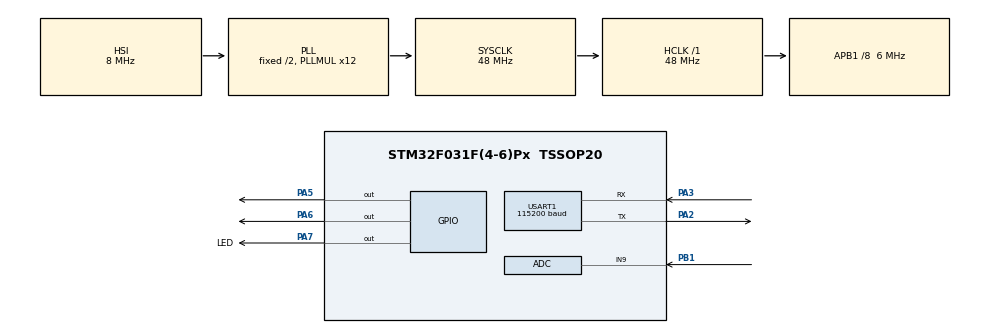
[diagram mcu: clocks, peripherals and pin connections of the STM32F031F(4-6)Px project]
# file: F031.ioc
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ADC.ClockPrescaler=ADC_CLOCK_ASYNC_DIV1
ADC.ContinuousConvMode=ENABLE
Dma.ADC.0.Direction=DMA_PERIPH_TO_MEMORY
Dma.ADC.0.Instance=DMA1_Channel1
Dma.ADC.0.MemDataAlignment=DMA_MDATAALIGN_HALFWORD
Dma.ADC.0.MemInc=DMA_MINC_ENABLE
Dma.ADC.0.Mode=DMA_NORMAL
Dma.ADC.0.PeriphDataAlignment=DMA_PDATAALIGN_HALFWORD
Dma.ADC.0.PeriphInc=DMA_PINC_DISABLE
Dma.ADC.0.Priority=DMA_PRIORITY_LOW
Dma.Request0=ADC
Dma.Request1=USART1_RX
Dma.Request2=USART1_TX
Dma.USART1_RX.1.Direction=DMA_PERIPH_TO_MEMORY
Dma.USART1_RX.1.Instance=DMA1_Channel3
Dma.USART1_RX.1.MemDataAlignment=DMA_MDATAALIGN_BYTE
Dma.USART1_RX.1.MemInc=DMA_MINC_ENABLE
Dma.USART1_RX.1.Mode=DMA_NORMAL
Dma.USART1_RX.1.PeriphDataAlignment=DMA_PDATAALIGN_BYTE
Dma.USART1_RX.1.PeriphInc=DMA_PINC_DISABLE
Dma.USART1_RX.1.Priority=DMA_PRIORITY_LOW
Dma.USART1_TX.2.Direction=DMA_MEMORY_TO_PERIPH
Dma.USART1_TX.2.Instance=DMA1_Channel2
Dma.USART1_TX.2.MemDataAlignment=DMA_MDATAALIGN_BYTE
Dma.USART1_TX.2.MemInc=DMA_MINC_ENABLE
Dma.USART1_TX.2.Mode=DMA_NORMAL
Dma.USART1_TX.2.PeriphDataAlignment=DMA_PDATAALIGN_BYTE
Dma.USART1_TX.2.PeriphInc=DMA_PINC_DISABLE
Dma.USART1_TX.2.Priority=DMA_PRIORITY_LOW
Mcu.Family=STM32F0
Mcu.Name=STM32F031F(4-6)Px
Mcu.Package=TSSOP20
NVIC.DMA1_Channel1_IRQn=true\:3\:0\:true\:false\:true\:false\:true\:true
NVIC.DMA1_Channel2_3_IRQn=true\:1\:0\:true\:false\:true\:false\:true\:true
NVIC.PVD_IRQn=true\:3\:0\:true\:false\:true\:true\:true\:true
PA13.Mode=Serial_Wire
PA13.Signal=SYS_SWDIO
PA14.Mode=Serial_Wire
PA14.Signal=SYS_SWCLK
PA2.Mode=Asynchronous
PA2.Signal=USART1_TX
PA3.Mode=Asynchronous
PA3.Signal=USART1_RX
PA5.Signal=GPIO_Output
PA6.Signal=GPIO_Output
PA7.GPIO_Label=LED
PA7.Signal=GPIO_Output
PB1.Mode=IN9
PB1.Signal=ADC_IN9
ProjectManager.HeapSize=0x200
ProjectManager.StackSize=0x400
ProjectManager.TargetToolchain=EWARM V7
RCC.AHBFreq_Value=48000000
RCC.APB1CLKDivider=RCC_HCLK_DIV8
RCC.APB1Freq_Value=6000000
RCC.APB1TimFreq_Value=12000000
RCC.HCLKFreq_Value=48000000
RCC.PLLMUL=RCC_PLL_MUL12
RCC.SYSCLKFreq_VALUE=48000000
RCC.SYSCLKSource=RCC_SYSCLKSOURCE_PLLCLK
RCC.Usart1ClockSelection=RCC_USART1CLKSOURCE_SYSCLK
USART1.BaudRate=115200
USART1.OverSampling=UART_OVERSAMPLING_8
USART1.VirtualMode-Asynchronous=VM_ASYNC
VP_ADC_TempSens_Input.Mode=IN-TempSens
VP_ADC_Vref_Input.Mode=IN-Vrefint
board=custom

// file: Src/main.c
/* USER CODE BEGIN Header */
/**
  ******************************************************************************
  * @file           : main.c
  * @brief          : Main program body
  ******************************************************************************
  * @attention
  *
  * Copyright (c) 2024 STMicroelectronics.
  * All rights reserved.
  *
  * This software is licensed under terms that can be found in the LICENSE file
  * in the root directory of this software component.
  * If no LICENSE file comes with this software, it is provided AS-IS.
  *
  ******************************************************************************
  */
/* USER CODE END Header */
#include "main.h"

ADC_HandleTypeDef hadc;
DMA_HandleTypeDef hdma_adc;

void SystemClock_Config(void);
static void MX_GPIO_Init(void);
static void MX_DMA_Init(void);
static void MX_USART1_UART_Init(void);
static void MX_ADC_Init(void);

int main(void)
{

  /* MCU Configuration--------------------------------------------------------*/

  /* Reset of all peripherals, Initializes the Flash interface and the Systick. */
  HAL_Init();

  /* Configure the system clock */
  SystemClock_Config();

  /* Initialize all configured peripherals */
  MX_GPIO_Init();
  MX_DMA_Init();
  MX_USART1_UART_Init();
  MX_ADC_Init();

  /* Infinite loop */
  while (1)
  {

    /* USER CODE BEGIN 3 */
    HAL_GPIO_TogglePin(GPIOA, GPIO_PIN_5);
    HAL_GPIO_TogglePin(GPIOA, GPIO_PIN_6);
    HAL_Delay(200);
  }
  /* USER CODE END 3 */
}

void SystemClock_Config(void)
{
  RCC_OscInitTypeDef RCC_OscInitStruct = {0};
  RCC_ClkInitTypeDef RCC_ClkInitStruct = {0};
  RCC_PeriphCLKInitTypeDef PeriphClkInit = {0};

  /** Initializes the RCC Oscillators according to the specified parameters
  * in the RCC_OscInitTypeDef structure.
  */
  RCC_OscInitStruct.OscillatorType = RCC_OSCILLATORTYPE_HSI|RCC_OSCILLATORTYPE_HSI14;
  RCC_OscInitStruct.HSIState = RCC_HSI_ON;
  RCC_OscInitStruct.HSI14State = RCC_HSI14_ON;
  RCC_OscInitStruct.HSICalibrationValue = RCC_HSICALIBRATION_DEFAULT;
  RCC_OscInitStruct.HSI14CalibrationValue = 16;
  RCC_OscInitStruct.PLL.PLLState = RCC_PLL_ON;
  RCC_OscInitStruct.PLL.PLLSource = RCC_PLLSOURCE_HSI;
  RCC_OscInitStruct.PLL.PLLMUL = RCC_PLL_MUL12;
  RCC_OscInitStruct.PLL.PREDIV = RCC_PREDIV_DIV1;
  if (HAL_RCC_OscConfig(&RCC_OscInitStruct) != HAL_OK)
  {
    Error_Handler();
  }

  /** Initializes the CPU, AHB and APB buses clocks
  */
  RCC_ClkInitStruct.ClockType = RCC_CLOCKTYPE_HCLK|RCC_CLOCKTYPE_SYSCLK
                              |RCC_CLOCKTYPE_PCLK1;
  RCC_ClkInitStruct.SYSCLKSource = RCC_SYSCLKSOURCE_PLLCLK;
  RCC_ClkInitStruct.AHBCLKDivider = RCC_SYSCLK_DIV1;
  RCC_ClkInitStruct.APB1CLKDivider = RCC_HCLK_DIV8;

  if (HAL_RCC_ClockConfig(&RCC_ClkInitStruct, FLASH_LATENCY_1) != HAL_OK)
  {
    Error_Handler();
  }
  PeriphClkInit.PeriphClockSelection = RCC_PERIPHCLK_USART1;
  PeriphClkInit.Usart1ClockSelection = RCC_USART1CLKSOURCE_SYSCLK;
  if (HAL_RCCEx_PeriphCLKConfig(&PeriphClkInit) != HAL_OK)
  {
    Error_Handler();
  }
}

static void MX_ADC_Init(void)
{

  ADC_ChannelConfTypeDef sConfig = {0};

  /** Configure the global features of the ADC (Clock, Resolution, Data Alignment and number of conversion)
  */
  hadc.Instance = ADC1;
  hadc.Init.ClockPrescaler = ADC_CLOCK_ASYNC_DIV1;
  hadc.Init.Resolution = ADC_RESOLUTION_12B;
  hadc.Init.DataAlign = ADC_DATAALIGN_RIGHT;
  hadc.Init.ScanConvMode = ADC_SCAN_DIRECTION_FORWARD;
  hadc.Init.EOCSelection = ADC_EOC_SINGLE_CONV;
  hadc.Init.LowPowerAutoWait = DISABLE;
  hadc.Init.LowPowerAutoPowerOff = DISABLE;
  hadc.Init.ContinuousConvMode = ENABLE;
  hadc.Init.DiscontinuousConvMode = DISABLE;
  hadc.Init.ExternalTrigConv = ADC_SOFTWARE_START;
  hadc.Init.ExternalTrigConvEdge = ADC_EXTERNALTRIGCONVEDGE_NONE;
  hadc.Init.DMAContinuousRequests = DISABLE;
  hadc.Init.Overrun = ADC_OVR_DATA_PRESERVED;
  if (HAL_ADC_Init(&hadc) != HAL_OK)
  {
    Error_Handler();
  }

  /** Configure for the selected ADC regular channel to be converted.
  */
  sConfig.Channel = ADC_CHANNEL_9;
  sConfig.Rank = ADC_RANK_CHANNEL_NUMBER;
  sConfig.SamplingTime = ADC_SAMPLETIME_1CYCLE_5;
  if (HAL_ADC_ConfigChannel(&hadc, &sConfig) != HAL_OK)
  {
    Error_Handler();
  }

  /** Configure for the selected ADC regular channel to be converted.
  */
  sConfig.Channel = ADC_CHANNEL_TEMPSENSOR;
  if (HAL_ADC_ConfigChannel(&hadc, &sConfig) != HAL_OK)
  {
    Error_Handler();
  }

  /** Configure for the selected ADC regular channel to be converted.
  */
  sConfig.Channel = ADC_CHANNEL_VREFINT;
  if (HAL_ADC_ConfigChannel(&hadc, &sConfig) != HAL_OK)
  {
    Error_Handler();
  }

}

static void MX_USART1_UART_Init(void)
{

  LL_USART_InitTypeDef USART_InitStruct = {0};

  LL_GPIO_InitTypeDef GPIO_InitStruct = {0};

  /* Peripheral clock enable */
  LL_APB1_GRP2_EnableClock(LL_APB1_GRP2_PERIPH_USART1);

  LL_AHB1_GRP1_EnableClock(LL_AHB1_GRP1_PERIPH_GPIOA);
  /**USART1 GPIO Configuration
  PA2   ------> USART1_TX
  PA3   ------> USART1_RX
  */
  GPIO_InitStruct.Pin = LL_GPIO_PIN_2;
  GPIO_InitStruct.Mode = LL_GPIO_MODE_ALTERNATE;
  GPIO_InitStruct.Speed = LL_GPIO_SPEED_FREQ_HIGH;
  GPIO_InitStruct.OutputType = LL_GPIO_OUTPUT_PUSHPULL;
  GPIO_InitStruct.Pull = LL_GPIO_PULL_NO;
  GPIO_InitStruct.Alternate = LL_GPIO_AF_1;
  LL_GPIO_Init(GPIOA, &GPIO_InitStruct);

  GPIO_InitStruct.Pin = LL_GPIO_PIN_3;
  GPIO_InitStruct.Mode = LL_GPIO_MODE_ALTERNATE;
  GPIO_InitStruct.Speed = LL_GPIO_SPEED_FREQ_HIGH;
  GPIO_InitStruct.OutputType = LL_GPIO_OUTPUT_PUSHPULL;
  GPIO_InitStruct.Pull = LL_GPIO_PULL_NO;
  GPIO_InitStruct.Alternate = LL_GPIO_AF_1;
  LL_GPIO_Init(GPIOA, &GPIO_InitStruct);

  /* USART1 DMA Init */

  /* USART1_RX Init */
  LL_DMA_SetDataTransferDirection(DMA1, LL_DMA_CHANNEL_3, LL_DMA_DIRECTION_PERIPH_TO_MEMORY);

  LL_DMA_SetChannelPriorityLevel(DMA1, LL_DMA_CHANNEL_3, LL_DMA_PRIORITY_LOW);

  LL_DMA_SetMode(DMA1, LL_DMA_CHANNEL_3, LL_DMA_MODE_NORMAL);

  LL_DMA_SetPeriphIncMode(DMA1, LL_DMA_CHANNEL_3, LL_DMA_PERIPH_NOINCREMENT);

  LL_DMA_SetMemoryIncMode(DMA1, LL_DMA_CHANNEL_3, LL_DMA_MEMORY_INCREMENT);

  LL_DMA_SetPeriphSize(DMA1, LL_DMA_CHANNEL_3, LL_DMA_PDATAALIGN_BYTE);

  LL_DMA_SetMemorySize(DMA1, LL_DMA_CHANNEL_3, LL_DMA_MDATAALIGN_BYTE);

  /* USART1_TX Init */
  LL_DMA_SetDataTransferDirection(DMA1, LL_DMA_CHANNEL_2, LL_DMA_DIRECTION_MEMORY_TO_PERIPH);

  LL_DMA_SetChannelPriorityLevel(DMA1, LL_DMA_CHANNEL_2, LL_DMA_PRIORITY_LOW);

  LL_DMA_SetMode(DMA1, LL_DMA_CHANNEL_2, LL_DMA_MODE_NORMAL);

  LL_DMA_SetPeriphIncMode(DMA1, LL_DMA_CHANNEL_2, LL_DMA_PERIPH_NOINCREMENT);

  LL_DMA_SetMemoryIncMode(DMA1, LL_DMA_CHANNEL_2, LL_DMA_MEMORY_INCREMENT);

  LL_DMA_SetPeriphSize(DMA1, LL_DMA_CHANNEL_2, LL_DMA_PDATAALIGN_BYTE);

  LL_DMA_SetMemorySize(DMA1, LL_DMA_CHANNEL_2, LL_DMA_MDATAALIGN_BYTE);

  USART_InitStruct.BaudRate = 115200;
  USART_InitStruct.DataWidth = LL_USART_DATAWIDTH_8B;
  USART_InitStruct.StopBits = LL_USART_STOPBITS_1;
  USART_InitStruct.Parity = LL_USART_PARITY_NONE;
  USART_InitStruct.TransferDirection = LL_USART_DIRECTION_TX_RX;
  USART_InitStruct.HardwareFlowControl = LL_USART_HWCONTROL_NONE;
  USART_InitStruct.OverSampling = LL_USART_OVERSAMPLING_8;
  LL_USART_Init(USART1, &USART_InitStruct);
  LL_USART_DisableIT_CTS(USART1);
  LL_USART_ConfigAsyncMode(USART1);
  LL_USART_Enable(USART1);

}

static void MX_DMA_Init(void)
{

  /* Init with LL driver */
  /* DMA controller clock enable */
  LL_AHB1_GRP1_EnableClock(LL_AHB1_GRP1_PERIPH_DMA1);

  /* DMA interrupt init */
  /* DMA1_Channel1_IRQn interrupt configuration */
  HAL_NVIC_SetPriority(DMA1_Channel1_IRQn, 3, 0);
  HAL_NVIC_EnableIRQ(DMA1_Channel1_IRQn);
  /* DMA1_Channel2_3_IRQn interrupt configuration */
  NVIC_SetPriority(DMA1_Channel2_3_IRQn, 1);
  NVIC_EnableIRQ(DMA1_Channel2_3_IRQn);

}

static void MX_GPIO_Init(void)
{
  GPIO_InitTypeDef GPIO_InitStruct = {0};

  /* GPIO Ports Clock Enable */
  __HAL_RCC_GPIOA_CLK_ENABLE();
  __HAL_RCC_GPIOB_CLK_ENABLE();

  /*Configure GPIO pin Output Level */
  HAL_GPIO_WritePin(GPIOA, GPIO_PIN_5|GPIO_PIN_6|LED_Pin, GPIO_PIN_RESET);

  /*Configure GPIO pins : PA5 PA6 LED_Pin */
  GPIO_InitStruct.Pin = GPIO_PIN_5|GPIO_PIN_6|LED_Pin;
  GPIO_InitStruct.Mode = GPIO_MODE_OUTPUT_PP;
  GPIO_InitStruct.Pull = GPIO_NOPULL;
  GPIO_InitStruct.Speed = GPIO_SPEED_FREQ_LOW;
  HAL_GPIO_Init(GPIOA, &GPIO_InitStruct);

}

void Error_Handler(void)
{
  __disable_irq();
  while (1)
  {
  }
}
